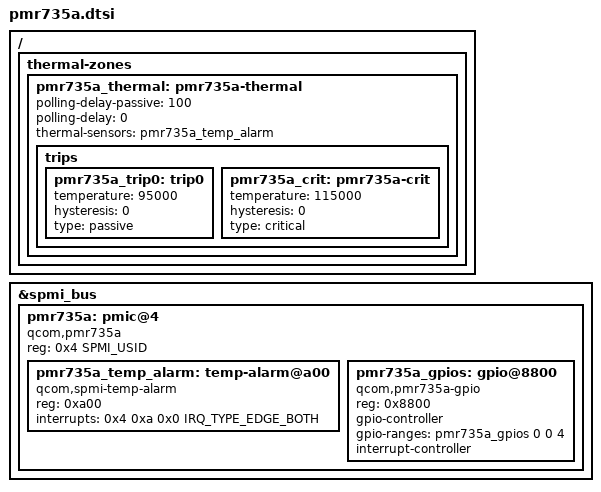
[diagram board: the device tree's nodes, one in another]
// SPDX-License-Identifier: BSD-3-Clause
/*
 * Copyright (c) 2021, Linaro Limited
 */

#include <dt-bindings/interrupt-controller/irq.h>
#include <dt-bindings/spmi/spmi.h>

&spmi_bus {
	pmr735a: pmic@4 {
		compatible = "qcom,pmr735a", "qcom,spmi-pmic";
		reg = <0x4 SPMI_USID>;
		#address-cells = <1>;
		#size-cells = <0>;

		pmr735a_temp_alarm: temp-alarm@a00 {
			compatible = "qcom,spmi-temp-alarm";
			reg = <0xa00>;
			interrupts = <0x4 0xa 0x0 IRQ_TYPE_EDGE_BOTH>;
			#thermal-sensor-cells = <0>;
		};

		pmr735a_gpios: gpio@8800 {
			compatible = "qcom,pmr735a-gpio", "qcom,spmi-gpio";
			reg = <0x8800>;
			gpio-controller;
			gpio-ranges = <&pmr735a_gpios 0 0 4>;
			#gpio-cells = <2>;
			interrupt-controller;
			#interrupt-cells = <2>;
		};
	};
};

/ {
	thermal-zones {
		pmr735a_thermal: pmr735a-thermal {
			polling-delay-passive = <100>;
			polling-delay = <0>;
			thermal-sensors = <&pmr735a_temp_alarm>;

			trips {
				pmr735a_trip0: trip0 {
					temperature = <95000>;
					hysteresis = <0>;
					type = "passive";
				};

				pmr735a_crit: pmr735a-crit {
					temperature = <115000>;
					hysteresis = <0>;
					type = "critical";
				};
			};
		};
	};
};
